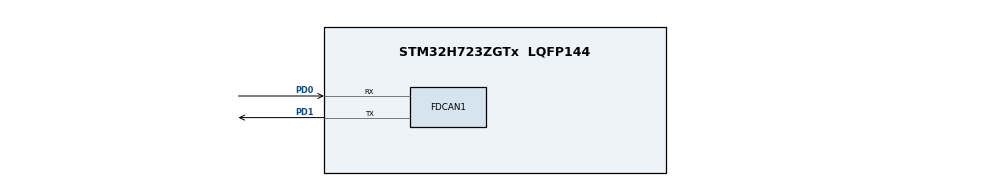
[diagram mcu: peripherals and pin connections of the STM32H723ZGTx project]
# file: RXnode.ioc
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CORTEX_M7.default_mode_Activation=1
FDCAN1.AutoRetransmission=ENABLE
FDCAN1.CalculateBaudRateNominal=1000000
FDCAN1.CalculateTimeBitNominal=1000
FDCAN1.CalculateTimeQuantumNominal=62.5
FDCAN1.DataSyncJumpWidth=6
FDCAN1.DataTimeSeg1=17
FDCAN1.DataTimeSeg2=6
FDCAN1.FrameFormat=FDCAN_FRAME_FD_BRS
FDCAN1.Mode=FDCAN_MODE_NORMAL
FDCAN1.NominalPrescaler=6
FDCAN1.NominalSyncJumpWidth=2
FDCAN1.NominalTimeSeg1=11
FDCAN1.NominalTimeSeg2=4
FDCAN1.RxBufferSize=FDCAN_DATA_BYTES_16
FDCAN1.RxBuffersNbr=0
FDCAN1.RxFifo0ElmtSize=FDCAN_DATA_BYTES_16
FDCAN1.RxFifo0ElmtsNbr=8
FDCAN1.RxFifo1ElmtSize=FDCAN_DATA_BYTES_16
FDCAN1.StdFiltersNbr=1
FDCAN1.TxElmtSize=FDCAN_DATA_BYTES_16
FDCAN1.TxFifoQueueElmtsNbr=0
Mcu.Family=STM32H7
Mcu.Name=STM32H723ZGTx
Mcu.Package=LQFP144
NUCLEO-H723ZG.BUTTON=1
NUCLEO-H723ZG.LD1=true
NUCLEO-H723ZG.LD2=true
NUCLEO-H723ZG.LD3=true
NUCLEO-H723ZG.VCP=true
NVIC.EXTI15_10_IRQn=true\:0\:0\:false\:false\:true\:false\:true\:true
NVIC.PriorityGroup=NVIC_PRIORITYGROUP_4
PA13(JTMS/SWDIO).GPIO_Label=SWDIO
PA13(JTMS/SWDIO).Signal=DEBUG_JTMS-SWDIO
PA14(JTCK/SWCLK).GPIO_Label=SWCLK
PA14(JTCK/SWCLK).Signal=DEBUG_JTCK-SWCLK
PC14-OSC32_IN.Signal=RCC_OSC32_IN
PC15-OSC32_OUT.Signal=RCC_OSC32_OUT
PD0.Mode=FDCAN_Activate
PD0.Signal=FDCAN1_RX
PD1.Mode=FDCAN_Activate
PD1.Signal=FDCAN1_TX
PD8.Signal=USART3_TX
PD9.Signal=USART3_RX
ProjectManager.HeapSize=0x200
ProjectManager.StackSize=0x400
ProjectManager.TargetToolchain=STM32CubeIDE
RCC.ADCFreq_Value=48000000
RCC.APB1Freq_Value=96000000
RCC.APB2Freq_Value=96000000
RCC.APB3Freq_Value=96000000
RCC.APB4Freq_Value=96000000
RCC.CortexFreq_Value=192000000
RCC.D1PPRE=RCC_APB3_DIV2
RCC.D2PPRE1=RCC_APB1_DIV2
RCC.D2PPRE2=RCC_APB2_DIV2
RCC.D3PPRE=RCC_APB4_DIV2
RCC.DIVM1=4
RCC.DIVM2=4
RCC.DIVN1=12
RCC.DIVN2=12
RCC.DIVP1=1
RCC.DIVP2=4
RCC.HCLKFreq_Value=192000000
RCC.HSE_VALUE=8000000
RCC.PLL2FRACN=0
RCC.PLLFRACN=0
RCC.SYSCLKFreq_VALUE=192000000
RCC.SYSCLKSource=RCC_SYSCLKSOURCE_PLLCLK
RCC.USBCLockSelection=RCC_USBCLKSOURCE_HSI48
RCC.USBFreq_Value=48000000
VP_MEMORYMAP_VS_MEMORYMAP.Mode=CurAppReg
VP_NUCLEO-H723ZG_VS_BSP_COMMON.Mode=COMMON
board=NUCLEO-H723ZG

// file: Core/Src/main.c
/* USER CODE BEGIN Header */
/**
  ******************************************************************************
  * @file           : main.c
  * @brief          : Main program body
  ******************************************************************************
  * @attention
  *
  * Copyright (c) 2026 STMicroelectronics.
  * All rights reserved.
  *
  * This software is licensed under terms that can be found in the LICENSE file
  * in the root directory of this software component.
  * If no LICENSE file comes with this software, it is provided AS-IS.
  *
  ******************************************************************************
  */
/* USER CODE END Header */
#include "main.h"

/* USER CODE BEGIN Includes */
#include <stdio.h>
#include <string.h>
#include "stm32h7xx_nucleo.h"
/* USER CODE END Includes */

COM_InitTypeDef BspCOMInit;

FDCAN_HandleTypeDef hfdcan1;

/* USER CODE BEGIN PV */
FDCAN_RxHeaderTypeDef g_rxHeader;
uint8_t g_rxData[16];

uint32_t g_rxId = 0;
uint32_t g_fifoLevel = 0;
uint32_t g_rxCount = 0;
uint32_t g_lastError = 0;

/* USER CODE END PV */

void SystemClock_Config(void);
static void MPU_Config(void);
static void MX_GPIO_Init(void);
static void MX_FDCAN1_Init(void);

int main(void)
{

  /* MPU Configuration--------------------------------------------------------*/
  MPU_Config();

  /* MCU Configuration--------------------------------------------------------*/

  /* Reset of all peripherals, Initializes the Flash interface and the Systick. */
  HAL_Init();

  /* Configure the system clock */
  SystemClock_Config();

  /* Initialize all configured peripherals */
  MX_GPIO_Init();
  MX_FDCAN1_Init();
  /* USER CODE BEGIN 2 */

  FDCAN_FilterTypeDef sFilterConfig;

  /* Accept ALL standard IDs */
  sFilterConfig.IdType = FDCAN_STANDARD_ID;
  sFilterConfig.FilterIndex = 0;
  sFilterConfig.FilterType = FDCAN_FILTER_MASK;
  sFilterConfig.FilterConfig = FDCAN_FILTER_TO_RXFIFO0;
  sFilterConfig.FilterID1 = 0x000;
  sFilterConfig.FilterID2 = 0x000;

  /* Configure filter BEFORE start */
  HAL_FDCAN_ConfigFilter(&hfdcan1, &sFilterConfig);

  /* FIX: Global filter måste vara EFTER init */
  HAL_FDCAN_ConfigGlobalFilter(&hfdcan1,
  FDCAN_ACCEPT_IN_RX_FIFO0,
  FDCAN_ACCEPT_IN_RX_FIFO0,
  FDCAN_REJECT_REMOTE,
  FDCAN_REJECT_REMOTE);

  /* Start FDCAN */
  HAL_FDCAN_Start(&hfdcan1);

  /* USER CODE END 2 */

  /* Initialize leds */
  BSP_LED_Init(LED_GREEN);
  BSP_LED_Init(LED_YELLOW);
  BSP_LED_Init(LED_RED);

  /* Initialize USER push-button, will be used to trigger an interrupt each time it's pressed.*/
  BSP_PB_Init(BUTTON_USER, BUTTON_MODE_EXTI);

  /* Initialize COM1 port (115200, 8 bits (7-bit data + 1 stop bit), no parity */
  BspCOMInit.BaudRate   = 115200;
  BspCOMInit.WordLength = COM_WORDLENGTH_8B;
  BspCOMInit.StopBits   = COM_STOPBITS_1;
  BspCOMInit.Parity     = COM_PARITY_NONE;
  BspCOMInit.HwFlowCtl  = COM_HWCONTROL_NONE;
  if (BSP_COM_Init(COM1, &BspCOMInit) != BSP_ERROR_NONE)
  {
    Error_Handler();
  }

  /* Infinite loop */
  /* USER CODE BEGIN WHILE */

  while (1)
  {
      g_fifoLevel = HAL_FDCAN_GetRxFifoFillLevel(&hfdcan1, FDCAN_RX_FIFO0);

      if (g_fifoLevel > 0)
      {
    	  if (HAL_FDCAN_GetRxMessage(&hfdcan1, FDCAN_RX_FIFO0, &g_rxHeader, g_rxData) == HAL_OK)
    	  {
    		  if (g_rxHeader.Identifier == 0x102)
    		  {
    		      if (g_rxHeader.DataLength == FDCAN_DLC_BYTES_16)
    		      {
    		          uint16_t samples[8];

    		          for (int i = 0; i < 8; i++)
    		          {
    		              samples[i] = (g_rxData[2*i] << 8) | g_rxData[2*i+1];
    		          }

    		          char msg[120];
    		          sprintf(msg, "%u %u %u %u %u %u %u %u\r\n",
    		                  samples[0], samples[1], samples[2], samples[3],
    		                  samples[4], samples[5], samples[6], samples[7]);

    		          sprintf(msg, "ID:0x%03X %u %u %u %u %u %u %u %u\r\n",
    		                  g_rxHeader.Identifier,
    		                  samples[0], samples[1], samples[2], samples[3],
    		                  samples[4], samples[5], samples[6], samples[7]);

    		          HAL_UART_Transmit(&hcom_uart[COM1], (uint8_t*)msg, strlen(msg), HAL_MAX_DELAY);
    		      }
    		  }
    	  }
      }

      HAL_Delay(1);
    /* USER CODE END WHILE */

  }
}

void SystemClock_Config(void)
{
  RCC_OscInitTypeDef RCC_OscInitStruct = {0};
  RCC_ClkInitTypeDef RCC_ClkInitStruct = {0};

  /** Supply configuration update enable
  */
  HAL_PWREx_ConfigSupply(PWR_LDO_SUPPLY);

  /** Configure the main internal regulator output voltage
  */
  __HAL_PWR_VOLTAGESCALING_CONFIG(PWR_REGULATOR_VOLTAGE_SCALE1);

  while(!__HAL_PWR_GET_FLAG(PWR_FLAG_VOSRDY)) {}

  /** Initializes the RCC Oscillators according to the specified parameters
  * in the RCC_OscInitTypeDef structure.
  */
  RCC_OscInitStruct.OscillatorType = RCC_OSCILLATORTYPE_HSI;
  RCC_OscInitStruct.HSIState = RCC_HSI_DIV1;
  RCC_OscInitStruct.HSICalibrationValue = 64;
  RCC_OscInitStruct.PLL.PLLState = RCC_PLL_ON;
  RCC_OscInitStruct.PLL.PLLSource = RCC_PLLSOURCE_HSI;
  RCC_OscInitStruct.PLL.PLLM = 4;
  RCC_OscInitStruct.PLL.PLLN = 12;
  RCC_OscInitStruct.PLL.PLLP = 1;
  RCC_OscInitStruct.PLL.PLLQ = 2;
  RCC_OscInitStruct.PLL.PLLR = 2;
  RCC_OscInitStruct.PLL.PLLRGE = RCC_PLL1VCIRANGE_3;
  RCC_OscInitStruct.PLL.PLLVCOSEL = RCC_PLL1VCOWIDE;
  RCC_OscInitStruct.PLL.PLLFRACN = 0;
  if (HAL_RCC_OscConfig(&RCC_OscInitStruct) != HAL_OK)
  {
    Error_Handler();
  }

  /** Initializes the CPU, AHB and APB buses clocks
  */
  RCC_ClkInitStruct.ClockType = RCC_CLOCKTYPE_HCLK|RCC_CLOCKTYPE_SYSCLK
                              |RCC_CLOCKTYPE_PCLK1|RCC_CLOCKTYPE_PCLK2
                              |RCC_CLOCKTYPE_D3PCLK1|RCC_CLOCKTYPE_D1PCLK1;
  RCC_ClkInitStruct.SYSCLKSource = RCC_SYSCLKSOURCE_PLLCLK;
  RCC_ClkInitStruct.SYSCLKDivider = RCC_SYSCLK_DIV1;
  RCC_ClkInitStruct.AHBCLKDivider = RCC_HCLK_DIV1;
  RCC_ClkInitStruct.APB3CLKDivider = RCC_APB3_DIV2;
  RCC_ClkInitStruct.APB1CLKDivider = RCC_APB1_DIV2;
  RCC_ClkInitStruct.APB2CLKDivider = RCC_APB2_DIV2;
  RCC_ClkInitStruct.APB4CLKDivider = RCC_APB4_DIV2;

  if (HAL_RCC_ClockConfig(&RCC_ClkInitStruct, FLASH_LATENCY_2) != HAL_OK)
  {
    Error_Handler();
  }
}

static void MX_FDCAN1_Init(void)
{

  hfdcan1.Instance = FDCAN1;
  hfdcan1.Init.FrameFormat = FDCAN_FRAME_FD_BRS;
  hfdcan1.Init.Mode = FDCAN_MODE_NORMAL;
  hfdcan1.Init.AutoRetransmission = ENABLE;
  hfdcan1.Init.TransmitPause = DISABLE;
  hfdcan1.Init.ProtocolException = DISABLE;
  hfdcan1.Init.NominalPrescaler = 6;
  hfdcan1.Init.NominalSyncJumpWidth = 2;
  hfdcan1.Init.NominalTimeSeg1 = 11;
  hfdcan1.Init.NominalTimeSeg2 = 4;
  hfdcan1.Init.DataPrescaler = 1;
  hfdcan1.Init.DataSyncJumpWidth = 6;
  hfdcan1.Init.DataTimeSeg1 = 17;
  hfdcan1.Init.DataTimeSeg2 = 6;
  hfdcan1.Init.MessageRAMOffset = 0;
  hfdcan1.Init.StdFiltersNbr = 1;
  hfdcan1.Init.ExtFiltersNbr = 0;
  hfdcan1.Init.RxFifo0ElmtsNbr = 8;
  hfdcan1.Init.RxFifo0ElmtSize = FDCAN_DATA_BYTES_16;
  hfdcan1.Init.RxFifo1ElmtsNbr = 0;
  hfdcan1.Init.RxFifo1ElmtSize = FDCAN_DATA_BYTES_16;
  hfdcan1.Init.RxBuffersNbr = 0;
  hfdcan1.Init.RxBufferSize = FDCAN_DATA_BYTES_16;
  hfdcan1.Init.TxEventsNbr = 0;
  hfdcan1.Init.TxBuffersNbr = 0;
  hfdcan1.Init.TxFifoQueueElmtsNbr = 0;
  hfdcan1.Init.TxFifoQueueMode = FDCAN_TX_FIFO_OPERATION;
  hfdcan1.Init.TxElmtSize = FDCAN_DATA_BYTES_16;
  if (HAL_FDCAN_Init(&hfdcan1) != HAL_OK)
  {
    Error_Handler();
  }

}

static void MX_GPIO_Init(void)
{

  /* GPIO Ports Clock Enable */
  __HAL_RCC_GPIOC_CLK_ENABLE();
  __HAL_RCC_GPIOA_CLK_ENABLE();
  __HAL_RCC_GPIOD_CLK_ENABLE();

}

 /* MPU Configuration */

void MPU_Config(void)
{
  MPU_Region_InitTypeDef MPU_InitStruct = {0};

  /* Disables the MPU */
  HAL_MPU_Disable();

  /** Initializes and configures the Region and the memory to be protected
  */
  MPU_InitStruct.Enable = MPU_REGION_ENABLE;
  MPU_InitStruct.Number = MPU_REGION_NUMBER0;
  MPU_InitStruct.BaseAddress = 0x0;
  MPU_InitStruct.Size = MPU_REGION_SIZE_4GB;
  MPU_InitStruct.SubRegionDisable = 0x87;
  MPU_InitStruct.TypeExtField = MPU_TEX_LEVEL0;
  MPU_InitStruct.AccessPermission = MPU_REGION_NO_ACCESS;
  MPU_InitStruct.DisableExec = MPU_INSTRUCTION_ACCESS_DISABLE;
  MPU_InitStruct.IsShareable = MPU_ACCESS_SHAREABLE;
  MPU_InitStruct.IsCacheable = MPU_ACCESS_NOT_CACHEABLE;
  MPU_InitStruct.IsBufferable = MPU_ACCESS_NOT_BUFFERABLE;

  HAL_MPU_ConfigRegion(&MPU_InitStruct);
  /* Enables the MPU */
  HAL_MPU_Enable(MPU_PRIVILEGED_DEFAULT);

}

void Error_Handler(void)
{
  __disable_irq();
  while (1)
  {
  }
}
